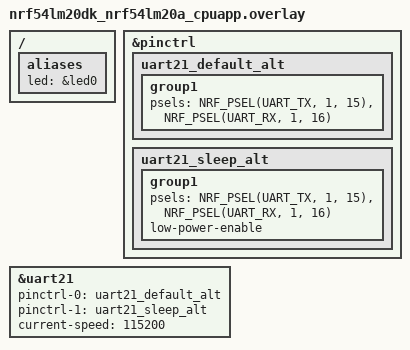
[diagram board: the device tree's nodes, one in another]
/*
 * Copyright (c) 2025 Nordic Semiconductor ASA
 *
 * SPDX-License-Identifier: LicenseRef-Nordic-5-Clause
 */

/ {
	aliases {
		led = &led0;
		/delete-property/ led1;
	};
};

/delete-node/ &led1;

/* Test requires following loopback:
 * P1.15 - P1.16
 */

&pinctrl {
	uart21_default_alt: uart21_default_alt {
		group1 {
			psels = <NRF_PSEL(UART_TX, 1, 15)>,
				<NRF_PSEL(UART_RX, 1, 16)>;
		};
	};

	uart21_sleep_alt: uart21_sleep_alt {
		group1 {
			psels = <NRF_PSEL(UART_TX, 1, 15)>,
				<NRF_PSEL(UART_RX, 1, 16)>;
			low-power-enable;
		};
	};
};

dut: &uart21 {
	status = "okay";
	pinctrl-0 = <&uart21_default_alt>;
	pinctrl-1 = <&uart21_sleep_alt>;
	pinctrl-names = "default", "sleep";
	current-speed = <115200>;
};
